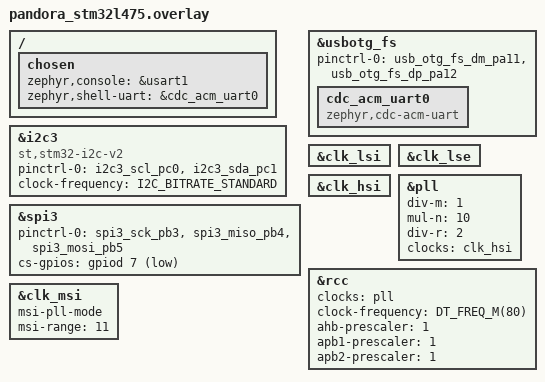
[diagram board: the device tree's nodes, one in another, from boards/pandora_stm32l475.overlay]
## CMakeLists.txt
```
# SPDX-License-Identifier: Apache-2.0

cmake_minimum_required(VERSION 3.20.0)

find_package(Zephyr REQUIRED HINTS $ENV{ZEPHYR_BASE})
project(hello_world)

include(${ZEPHYR_BASE}/samples/subsys/usb/common/common.cmake)
FILE(GLOB app_sources src/*.c)
target_sources(app PRIVATE ${app_sources})
```

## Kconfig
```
# Copyright (c) 2023 Nordic Semiconductor ASA
# SPDX-License-Identifier: Apache-2.0

# Source common USB sample options used to initialize new experimental USB
# device stack. The scope of these options is limited to USB samples in project
# tree, you cannot use them in your own application.
source "samples/subsys/usb/common/Kconfig.sample_usbd"

source "Kconfig.zephyr"
```

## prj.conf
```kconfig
# CONFIG_INIT_STACKS is not set
CONFIG_HW_STACK_PROTECTION=y
CONFIG_GPIO=y
CONFIG_LOG=y
CONFIG_CONSOLE=y
CONFIG_ARM_MPU=y
# CONFIG_THREAD_MONITOR is not set
# CONFIG_THREAD_NAME is not set
CONFIG_UART_CONSOLE=y
CONFIG_DISPLAY=y
CONFIG_UART_LINE_CTRL=y
# CONFIG_USB_DEVICE_REMOTE_WAKEUP is not set
CONFIG_LOG_MODE_IMMEDIATE=y
# CONFIG_LOG_RUNTIME_FILTERING is not set
CONFIG_LOG_BACKEND_UART=y
CONFIG_SHELL=y
CONFIG_USB_DEVICE_STACK=y
CONFIG_USB_DEVICE_PID=0x0004
CONFIG_USB_DEVICE_PRODUCT="Zephyr USB console sample"
```

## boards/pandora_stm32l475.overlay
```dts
/ {
	chosen {
		zephyr,console = &usart1;
		zephyr,shell-uart = &cdc_acm_uart0;
	};
};

&i2c3 {
	compatible = "st,stm32-i2c-v2";
	pinctrl-0 = <&i2c3_scl_pc0 &i2c3_sda_pc1>;
	pinctrl-names = "default";
	clock-frequency = <I2C_BITRATE_STANDARD>;
	status = "okay";
};

&spi3 {
	status = "okay";

	pinctrl-0 = <&spi3_sck_pb3 &spi3_miso_pb4 &spi3_mosi_pb5>;
	pinctrl-names = "default";

	cs-gpios = <&gpiod 7 GPIO_ACTIVE_LOW>;
};

zephyr_udc0: &usbotg_fs {
	pinctrl-0 = <&usb_otg_fs_dm_pa11 &usb_otg_fs_dp_pa12>;
	pinctrl-names = "default";
	status = "okay";
};

&zephyr_udc0 {
	cdc_acm_uart0: cdc_acm_uart0 {
		compatible = "zephyr,cdc-acm-uart";
	};
};

&clk_lsi {
    status = "okay";
};
 
&clk_lse {
    status = "okay";
};
 
&clk_hsi {
    status = "okay";
};
 
&pll {
    div-m = <1>;
    mul-n = <10>;
    div-r = <2>;
    clocks = <&clk_hsi>;
    status = "okay";
};
 
&rcc {
    clocks = <&pll>;
    clock-frequency = <DT_FREQ_M(80)>;
    ahb-prescaler = <1>;
    apb1-prescaler = <1>;
    apb2-prescaler = <1>;
};
 
&clk_msi {
    status = "okay";
    msi-pll-mode;
    msi-range = <11>; /* to get 48MHz */
};
```

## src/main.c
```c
/*
 * Copyright (c) 2016 Intel Corporation.
 *
 * SPDX-License-Identifier: Apache-2.0
 */

#include <sample_usbd.h>

#include <zephyr/kernel.h>
#include <zephyr/sys/printk.h>
#include <zephyr/usb/usb_device.h>
#include <zephyr/usb/usbd.h>
#include <zephyr/drivers/uart.h>

BUILD_ASSERT(DT_NODE_HAS_COMPAT(DT_CHOSEN(zephyr_shell_uart), zephyr_cdc_acm_uart),
	     "Console device is not ACM CDC UART device");

int main(void)
{
    const struct device *const dev = DEVICE_DT_GET(DT_CHOSEN(zephyr_shell_uart));
	uint32_t dtr = 0;

	if (usb_enable(NULL)) {
		return 0;
	}

	/* Poll if the DTR flag was set */
	while (!dtr) {
		uart_line_ctrl_get(dev, UART_LINE_CTRL_DTR, &dtr);
		/* Give CPU resources to low priority threads. */
		k_sleep(K_MSEC(100));
	}

	while (1) {
		printf("Hello Console! %s\n", CONFIG_ARCH); // Print to console only
		printk("Hello Kernel! %s\n", CONFIG_ARCH); // Print to both console and shell
		k_sleep(K_SECONDS(1));
	}
}
```
